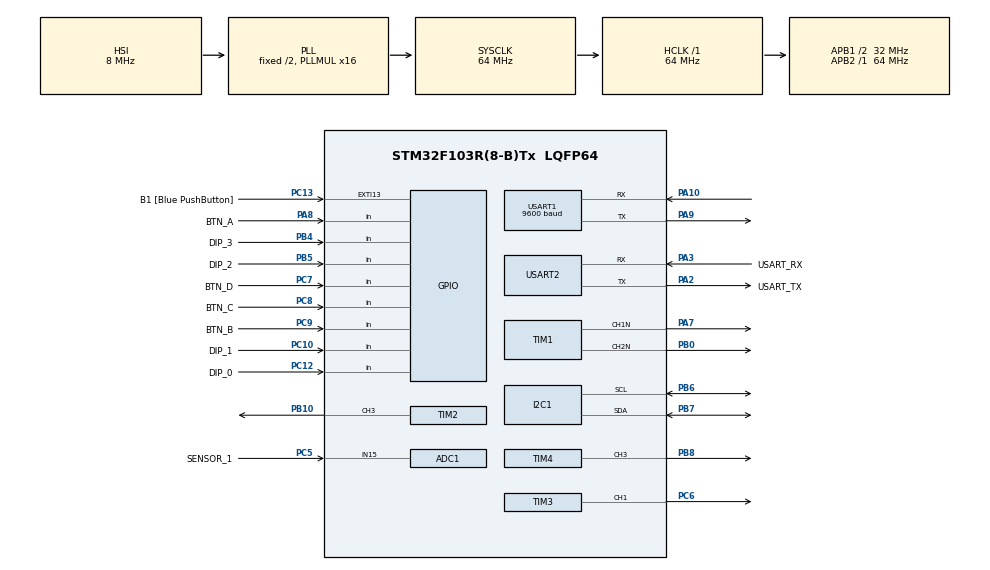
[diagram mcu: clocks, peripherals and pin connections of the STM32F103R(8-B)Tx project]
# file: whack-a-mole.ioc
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ADC1.Channel-0\#ChannelRegularConversion=ADC_CHANNEL_15
ADC1.ContinuousConvMode=DISABLE
ADC1.NbrOfConversion=1
ADC1.NbrOfConversionFlag=1
ADC1.Rank-0\#ChannelRegularConversion=1
ADC1.SamplingTime-0\#ChannelRegularConversion=ADC_SAMPLETIME_1CYCLE_5
ADC1.master=1
Mcu.Family=STM32F1
Mcu.Name=STM32F103R(8-B)Tx
Mcu.Package=LQFP64
NVIC.ADC1_2_IRQn=true\:0\:0\:false\:false\:true\:true\:true\:true
NVIC.EXTI15_10_IRQn=true\:0\:0\:false\:false\:true\:true\:true\:true
NVIC.PriorityGroup=NVIC_PRIORITYGROUP_4
NVIC.USART1_IRQn=true\:0\:0\:false\:false\:true\:true\:true\:true
PA10.Mode=Asynchronous
PA10.Signal=USART1_RX
PA13.GPIO_Label=TMS
PA13.Mode=Serial_Wire
PA13.Signal=SYS_JTMS-SWDIO
PA14.GPIO_Label=TCK
PA14.Mode=Serial_Wire
PA14.Signal=SYS_JTCK-SWCLK
PA2.GPIO_Label=USART_TX
PA2.GPIO_Mode=GPIO_MODE_AF_PP
PA2.GPIO_PuPd=GPIO_NOPULL
PA2.GPIO_Speed=GPIO_SPEED_FREQ_LOW
PA2.Mode=Asynchronous
PA2.Signal=USART2_TX
PA3.GPIO_Label=USART_RX
PA3.GPIO_Mode=GPIO_MODE_AF_PP
PA3.GPIO_PuPd=GPIO_NOPULL
PA3.GPIO_Speed=GPIO_SPEED_FREQ_LOW
PA3.Mode=Asynchronous
PA3.Signal=USART2_RX
PA7.Mode=PWM Generation1 CH1N
PA7.Signal=TIM1_CH1N
PA8.GPIO_Label=BTN_A
PA8.GPIO_PuPd=GPIO_PULLUP
PA8.Signal=GPIO_Input
PA9.Mode=Asynchronous
PA9.Signal=USART1_TX
PB0.Mode=PWM Generation2 CH2N
PB0.Signal=TIM1_CH2N
PB10.Signal=S_TIM2_CH3
PB11.Signal=I2C2_SDA
PB3.GPIO_Label=SWO
PB3.Signal=SYS_JTDO-TRACESWO
PB4.GPIO_Label=DIP_3
PB4.GPIO_PuPd=GPIO_PULLUP
PB4.Signal=GPIO_Input
PB5.GPIO_Label=DIP_2
PB5.GPIO_PuPd=GPIO_PULLUP
PB5.Signal=GPIO_Input
PB6.Mode=I2C
PB6.Signal=I2C1_SCL
PB7.Mode=I2C
PB7.Signal=I2C1_SDA
PB8.Signal=S_TIM4_CH3
PC10.GPIO_Label=DIP_1
PC10.GPIO_PuPd=GPIO_PULLUP
PC10.Signal=GPIO_Input
PC12.GPIO_Label=DIP_0
PC12.GPIO_PuPd=GPIO_PULLUP
PC12.Signal=GPIO_Input
PC13-TAMPER-RTC.GPIO_Label=B1 [Blue PushButton]
PC13-TAMPER-RTC.GPIO_PuPd=GPIO_NOPULL
PC13-TAMPER-RTC.Signal=GPXTI13
PC14-OSC32_IN.Mode=LSE-External-Oscillator
PC14-OSC32_IN.Signal=RCC_OSC32_IN
PC15-OSC32_OUT.Mode=LSE-External-Oscillator
PC15-OSC32_OUT.Signal=RCC_OSC32_OUT
PC5.GPIO_Label=SENSOR_1
PC5.Signal=ADCx_IN15
PC6.Signal=S_TIM3_CH1
PC7.GPIO_Label=BTN_D
PC7.GPIO_PuPd=GPIO_PULLUP
PC7.Signal=GPIO_Input
PC8.GPIO_Label=BTN_C
PC8.GPIO_PuPd=GPIO_PULLUP
PC8.Signal=GPIO_Input
PC9.GPIO_Label=BTN_B
PC9.GPIO_PuPd=GPIO_PULLUP
PC9.Signal=GPIO_Input
PD0-OSC_IN.Mode=HSE-External-Clock-Source
PD0-OSC_IN.Signal=RCC_OSC_IN
PD1-OSC_OUT.Mode=HSE-External-Clock-Source
PD1-OSC_OUT.Signal=RCC_OSC_OUT
ProjectManager.HeapSize=0x200
ProjectManager.StackSize=0x400
ProjectManager.TargetToolchain=STM32CubeIDE
RCC.ADCPresc=RCC_ADCPCLK2_DIV6
RCC.AHBFreq_Value=64000000
RCC.APB1CLKDivider=RCC_HCLK_DIV2
RCC.APB1Freq_Value=32000000
RCC.APB1TimFreq_Value=64000000
RCC.APB2Freq_Value=64000000
RCC.APB2TimFreq_Value=64000000
RCC.HCLKFreq_Value=64000000
RCC.PLLMUL=RCC_PLL_MUL16
RCC.RTCClockSelection=RCC_RTCCLKSOURCE_LSE
RCC.SYSCLKFreq_VALUE=64000000
RCC.SYSCLKSource=RCC_SYSCLKSOURCE_PLLCLK
RCC.USBFreq_Value=64000000
SH.ADCx_IN15.0=ADC1_IN15,IN15
SH.S_TIM2_CH3.0=TIM2_CH3,PWM Generation3 CH3
SH.S_TIM3_CH1.0=TIM3_CH1,PWM Generation1 CH1
SH.S_TIM4_CH3.0=TIM4_CH3,PWM Generation3 CH3
TIM1.Channel-PWM\ Generation1\ CH1N=TIM_CHANNEL_1
TIM1.Channel-PWM\ Generation2\ CH2N=TIM_CHANNEL_2
TIM2.Channel-PWM\ Generation3\ CH3=TIM_CHANNEL_3
TIM3.Channel-PWM\ Generation1\ CH1=TIM_CHANNEL_1
TIM4.Channel-PWM\ Generation3\ CH3=TIM_CHANNEL_3
USART1.BaudRate=9600
USART1.VirtualMode=VM_ASYNC
USART2.VirtualMode=VM_ASYNC
board=NUCLEO-F103RB

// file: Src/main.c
/* USER CODE BEGIN Header */
/**
  ******************************************************************************
  * @file           : main.c
  * @brief          : Main program body
  ******************************************************************************
  * @attention
  *
  * Copyright (c) 2026 STMicroelectronics.
  * All rights reserved.
  *
  * This software is licensed under terms that can be found in the LICENSE file
  * in the root directory of this software component.
  * If no LICENSE file comes with this software, it is provided AS-IS.
  *
  ******************************************************************************
  */
/* USER CODE END Header */
#include "main.h"

/* USER CODE BEGIN Includes */
#include "task_scheduler.h"
#include "lcd.h"
#include "low_power.h"

/* USER CODE END Includes */

ADC_HandleTypeDef hadc1;

I2C_HandleTypeDef hi2c1;

TIM_HandleTypeDef htim1;
TIM_HandleTypeDef htim2;
TIM_HandleTypeDef htim3;
TIM_HandleTypeDef htim4;

UART_HandleTypeDef huart1;
UART_HandleTypeDef huart2;

void SystemClock_Config(void);
static void MX_GPIO_Init(void);
static void MX_USART2_UART_Init(void);
static void MX_TIM3_Init(void);
static void MX_TIM1_Init(void);
static void MX_TIM2_Init(void);
static void MX_TIM4_Init(void);
static void MX_ADC1_Init(void);
static void MX_I2C1_Init(void);
static void MX_USART1_UART_Init(void);

int main(void)
{

  /* MCU Configuration--------------------------------------------------------*/

  /* Reset of all peripherals, Initializes the Flash interface and the Systick. */
  HAL_Init();

  /* Configure the system clock */
  SystemClock_Config();

  /* Initialize all configured peripherals */
  MX_GPIO_Init();
  MX_USART2_UART_Init();
  MX_TIM3_Init();
  MX_TIM1_Init();
  MX_TIM2_Init();
  MX_TIM4_Init();
  MX_ADC1_Init();
  MX_I2C1_Init();
  MX_USART1_UART_Init();
  /* USER CODE BEGIN 2 */
  schedulerInit();

  /* USER CODE END 2 */

  /* Infinite loop */
  /* USER CODE BEGIN WHILE */
  while (1)
  {
	  schedulerUpdate();
	  lowPowerEnterIdle();

    /* USER CODE END WHILE */

  }
}

void SystemClock_Config(void)
{
  RCC_OscInitTypeDef RCC_OscInitStruct = {0};
  RCC_ClkInitTypeDef RCC_ClkInitStruct = {0};
  RCC_PeriphCLKInitTypeDef PeriphClkInit = {0};

  /** Initializes the RCC Oscillators according to the specified parameters
  * in the RCC_OscInitTypeDef structure.
  */
  RCC_OscInitStruct.OscillatorType = RCC_OSCILLATORTYPE_HSI;
  RCC_OscInitStruct.HSIState = RCC_HSI_ON;
  RCC_OscInitStruct.HSICalibrationValue = RCC_HSICALIBRATION_DEFAULT;
  RCC_OscInitStruct.PLL.PLLState = RCC_PLL_ON;
  RCC_OscInitStruct.PLL.PLLSource = RCC_PLLSOURCE_HSI_DIV2;
  RCC_OscInitStruct.PLL.PLLMUL = RCC_PLL_MUL16;
  if (HAL_RCC_OscConfig(&RCC_OscInitStruct) != HAL_OK)
  {
    Error_Handler();
  }

  /** Initializes the CPU, AHB and APB buses clocks
  */
  RCC_ClkInitStruct.ClockType = RCC_CLOCKTYPE_HCLK|RCC_CLOCKTYPE_SYSCLK
                              |RCC_CLOCKTYPE_PCLK1|RCC_CLOCKTYPE_PCLK2;
  RCC_ClkInitStruct.SYSCLKSource = RCC_SYSCLKSOURCE_PLLCLK;
  RCC_ClkInitStruct.AHBCLKDivider = RCC_SYSCLK_DIV1;
  RCC_ClkInitStruct.APB1CLKDivider = RCC_HCLK_DIV2;
  RCC_ClkInitStruct.APB2CLKDivider = RCC_HCLK_DIV1;

  if (HAL_RCC_ClockConfig(&RCC_ClkInitStruct, FLASH_LATENCY_2) != HAL_OK)
  {
    Error_Handler();
  }
  PeriphClkInit.PeriphClockSelection = RCC_PERIPHCLK_ADC;
  PeriphClkInit.AdcClockSelection = RCC_ADCPCLK2_DIV6;
  if (HAL_RCCEx_PeriphCLKConfig(&PeriphClkInit) != HAL_OK)
  {
    Error_Handler();
  }
}

static void MX_ADC1_Init(void)
{

  ADC_ChannelConfTypeDef sConfig = {0};

  /** Common config
  */
  hadc1.Instance = ADC1;
  hadc1.Init.ScanConvMode = ADC_SCAN_DISABLE;
  hadc1.Init.ContinuousConvMode = DISABLE;
  hadc1.Init.DiscontinuousConvMode = DISABLE;
  hadc1.Init.ExternalTrigConv = ADC_SOFTWARE_START;
  hadc1.Init.DataAlign = ADC_DATAALIGN_RIGHT;
  hadc1.Init.NbrOfConversion = 1;
  if (HAL_ADC_Init(&hadc1) != HAL_OK)
  {
    Error_Handler();
  }

  /** Configure Regular Channel
  */
  sConfig.Channel = ADC_CHANNEL_15;
  sConfig.Rank = ADC_REGULAR_RANK_1;
  sConfig.SamplingTime = ADC_SAMPLETIME_1CYCLE_5;
  if (HAL_ADC_ConfigChannel(&hadc1, &sConfig) != HAL_OK)
  {
    Error_Handler();
  }

}

static void MX_I2C1_Init(void)
{

  hi2c1.Instance = I2C1;
  hi2c1.Init.ClockSpeed = 100000;
  hi2c1.Init.DutyCycle = I2C_DUTYCYCLE_2;
  hi2c1.Init.OwnAddress1 = 0;
  hi2c1.Init.AddressingMode = I2C_ADDRESSINGMODE_7BIT;
  hi2c1.Init.DualAddressMode = I2C_DUALADDRESS_DISABLE;
  hi2c1.Init.OwnAddress2 = 0;
  hi2c1.Init.GeneralCallMode = I2C_GENERALCALL_DISABLE;
  hi2c1.Init.NoStretchMode = I2C_NOSTRETCH_DISABLE;
  if (HAL_I2C_Init(&hi2c1) != HAL_OK)
  {
    Error_Handler();
  }

}

static void MX_TIM1_Init(void)
{

  TIM_MasterConfigTypeDef sMasterConfig = {0};
  TIM_OC_InitTypeDef sConfigOC = {0};
  TIM_BreakDeadTimeConfigTypeDef sBreakDeadTimeConfig = {0};

  htim1.Instance = TIM1;
  htim1.Init.Prescaler = 0;
  htim1.Init.CounterMode = TIM_COUNTERMODE_UP;
  htim1.Init.Period = 65535;
  htim1.Init.ClockDivision = TIM_CLOCKDIVISION_DIV1;
  htim1.Init.RepetitionCounter = 0;
  htim1.Init.AutoReloadPreload = TIM_AUTORELOAD_PRELOAD_DISABLE;
  if (HAL_TIM_PWM_Init(&htim1) != HAL_OK)
  {
    Error_Handler();
  }
  sMasterConfig.MasterOutputTrigger = TIM_TRGO_RESET;
  sMasterConfig.MasterSlaveMode = TIM_MASTERSLAVEMODE_DISABLE;
  if (HAL_TIMEx_MasterConfigSynchronization(&htim1, &sMasterConfig) != HAL_OK)
  {
    Error_Handler();
  }
  sConfigOC.OCMode = TIM_OCMODE_PWM1;
  sConfigOC.Pulse = 0;
  sConfigOC.OCPolarity = TIM_OCPOLARITY_HIGH;
  sConfigOC.OCNPolarity = TIM_OCNPOLARITY_HIGH;
  sConfigOC.OCFastMode = TIM_OCFAST_DISABLE;
  sConfigOC.OCIdleState = TIM_OCIDLESTATE_RESET;
  sConfigOC.OCNIdleState = TIM_OCNIDLESTATE_RESET;
  if (HAL_TIM_PWM_ConfigChannel(&htim1, &sConfigOC, TIM_CHANNEL_1) != HAL_OK)
  {
    Error_Handler();
  }
  if (HAL_TIM_PWM_ConfigChannel(&htim1, &sConfigOC, TIM_CHANNEL_2) != HAL_OK)
  {
    Error_Handler();
  }
  sBreakDeadTimeConfig.OffStateRunMode = TIM_OSSR_DISABLE;
  sBreakDeadTimeConfig.OffStateIDLEMode = TIM_OSSI_DISABLE;
  sBreakDeadTimeConfig.LockLevel = TIM_LOCKLEVEL_OFF;
  sBreakDeadTimeConfig.DeadTime = 0;
  sBreakDeadTimeConfig.BreakState = TIM_BREAK_DISABLE;
  sBreakDeadTimeConfig.BreakPolarity = TIM_BREAKPOLARITY_HIGH;
  sBreakDeadTimeConfig.AutomaticOutput = TIM_AUTOMATICOUTPUT_DISABLE;
  if (HAL_TIMEx_ConfigBreakDeadTime(&htim1, &sBreakDeadTimeConfig) != HAL_OK)
  {
    Error_Handler();
  }
  HAL_TIM_MspPostInit(&htim1);

}

static void MX_TIM2_Init(void)
{

  TIM_MasterConfigTypeDef sMasterConfig = {0};
  TIM_OC_InitTypeDef sConfigOC = {0};

  htim2.Instance = TIM2;
  htim2.Init.Prescaler = 0;
  htim2.Init.CounterMode = TIM_COUNTERMODE_UP;
  htim2.Init.Period = 65535;
  htim2.Init.ClockDivision = TIM_CLOCKDIVISION_DIV1;
  htim2.Init.AutoReloadPreload = TIM_AUTORELOAD_PRELOAD_DISABLE;
  if (HAL_TIM_PWM_Init(&htim2) != HAL_OK)
  {
    Error_Handler();
  }
  sMasterConfig.MasterOutputTrigger = TIM_TRGO_RESET;
  sMasterConfig.MasterSlaveMode = TIM_MASTERSLAVEMODE_DISABLE;
  if (HAL_TIMEx_MasterConfigSynchronization(&htim2, &sMasterConfig) != HAL_OK)
  {
    Error_Handler();
  }
  sConfigOC.OCMode = TIM_OCMODE_PWM1;
  sConfigOC.Pulse = 0;
  sConfigOC.OCPolarity = TIM_OCPOLARITY_HIGH;
  sConfigOC.OCFastMode = TIM_OCFAST_DISABLE;
  if (HAL_TIM_PWM_ConfigChannel(&htim2, &sConfigOC, TIM_CHANNEL_3) != HAL_OK)
  {
    Error_Handler();
  }
  HAL_TIM_MspPostInit(&htim2);

}

static void MX_TIM3_Init(void)
{

  TIM_MasterConfigTypeDef sMasterConfig = {0};
  TIM_OC_InitTypeDef sConfigOC = {0};

  htim3.Instance = TIM3;
  htim3.Init.Prescaler = 0;
  htim3.Init.CounterMode = TIM_COUNTERMODE_UP;
  htim3.Init.Period = 65535;
  htim3.Init.ClockDivision = TIM_CLOCKDIVISION_DIV1;
  htim3.Init.AutoReloadPreload = TIM_AUTORELOAD_PRELOAD_DISABLE;
  if (HAL_TIM_PWM_Init(&htim3) != HAL_OK)
  {
    Error_Handler();
  }
  sMasterConfig.MasterOutputTrigger = TIM_TRGO_RESET;
  sMasterConfig.MasterSlaveMode = TIM_MASTERSLAVEMODE_DISABLE;
  if (HAL_TIMEx_MasterConfigSynchronization(&htim3, &sMasterConfig) != HAL_OK)
  {
    Error_Handler();
  }
  sConfigOC.OCMode = TIM_OCMODE_PWM1;
  sConfigOC.Pulse = 0;
  sConfigOC.OCPolarity = TIM_OCPOLARITY_HIGH;
  sConfigOC.OCFastMode = TIM_OCFAST_DISABLE;
  if (HAL_TIM_PWM_ConfigChannel(&htim3, &sConfigOC, TIM_CHANNEL_1) != HAL_OK)
  {
    Error_Handler();
  }
  HAL_TIM_MspPostInit(&htim3);

}

static void MX_TIM4_Init(void)
{

  TIM_MasterConfigTypeDef sMasterConfig = {0};
  TIM_OC_InitTypeDef sConfigOC = {0};

  htim4.Instance = TIM4;
  htim4.Init.Prescaler = 0;
  htim4.Init.CounterMode = TIM_COUNTERMODE_UP;
  htim4.Init.Period = 65535;
  htim4.Init.ClockDivision = TIM_CLOCKDIVISION_DIV1;
  htim4.Init.AutoReloadPreload = TIM_AUTORELOAD_PRELOAD_DISABLE;
  if (HAL_TIM_PWM_Init(&htim4) != HAL_OK)
  {
    Error_Handler();
  }
  sMasterConfig.MasterOutputTrigger = TIM_TRGO_RESET;
  sMasterConfig.MasterSlaveMode = TIM_MASTERSLAVEMODE_DISABLE;
  if (HAL_TIMEx_MasterConfigSynchronization(&htim4, &sMasterConfig) != HAL_OK)
  {
    Error_Handler();
  }
  sConfigOC.OCMode = TIM_OCMODE_PWM1;
  sConfigOC.Pulse = 0;
  sConfigOC.OCPolarity = TIM_OCPOLARITY_HIGH;
  sConfigOC.OCFastMode = TIM_OCFAST_DISABLE;
  if (HAL_TIM_PWM_ConfigChannel(&htim4, &sConfigOC, TIM_CHANNEL_3) != HAL_OK)
  {
    Error_Handler();
  }
  HAL_TIM_MspPostInit(&htim4);

}

static void MX_USART1_UART_Init(void)
{

  huart1.Instance = USART1;
  huart1.Init.BaudRate = 9600;
  huart1.Init.WordLength = UART_WORDLENGTH_8B;
  huart1.Init.StopBits = UART_STOPBITS_1;
  huart1.Init.Parity = UART_PARITY_NONE;
  huart1.Init.Mode = UART_MODE_TX_RX;
  huart1.Init.HwFlowCtl = UART_HWCONTROL_NONE;
  huart1.Init.OverSampling = UART_OVERSAMPLING_16;
  if (HAL_UART_Init(&huart1) != HAL_OK)
  {
    Error_Handler();
  }

}

static void MX_USART2_UART_Init(void)
{

  huart2.Instance = USART2;
  huart2.Init.BaudRate = 115200;
  huart2.Init.WordLength = UART_WORDLENGTH_8B;
  huart2.Init.StopBits = UART_STOPBITS_1;
  huart2.Init.Parity = UART_PARITY_NONE;
  huart2.Init.Mode = UART_MODE_TX_RX;
  huart2.Init.HwFlowCtl = UART_HWCONTROL_NONE;
  huart2.Init.OverSampling = UART_OVERSAMPLING_16;
  if (HAL_UART_Init(&huart2) != HAL_OK)
  {
    Error_Handler();
  }

}

static void MX_GPIO_Init(void)
{
  GPIO_InitTypeDef GPIO_InitStruct = {0};

  /* GPIO Ports Clock Enable */
  __HAL_RCC_GPIOC_CLK_ENABLE();
  __HAL_RCC_GPIOD_CLK_ENABLE();
  __HAL_RCC_GPIOA_CLK_ENABLE();
  __HAL_RCC_GPIOB_CLK_ENABLE();

  /*Configure GPIO pin : B1_Pin */
  GPIO_InitStruct.Pin = B1_Pin;
  GPIO_InitStruct.Mode = GPIO_MODE_IT_RISING;
  GPIO_InitStruct.Pull = GPIO_NOPULL;
  HAL_GPIO_Init(B1_GPIO_Port, &GPIO_InitStruct);

  /*Configure GPIO pin : PB11 */
  GPIO_InitStruct.Pin = GPIO_PIN_11;
  GPIO_InitStruct.Mode = GPIO_MODE_AF_OD;
  GPIO_InitStruct.Speed = GPIO_SPEED_FREQ_HIGH;
  HAL_GPIO_Init(GPIOB, &GPIO_InitStruct);

  /*Configure GPIO pins : BTN_D_Pin BTN_C_Pin BTN_B_Pin DIP_1_Pin
                           DIP_0_Pin */
  GPIO_InitStruct.Pin = BTN_D_Pin|BTN_C_Pin|BTN_B_Pin|DIP_1_Pin
                          |DIP_0_Pin;
  GPIO_InitStruct.Mode = GPIO_MODE_INPUT;
  GPIO_InitStruct.Pull = GPIO_PULLUP;
  HAL_GPIO_Init(GPIOC, &GPIO_InitStruct);

  /*Configure GPIO pin : BTN_A_Pin */
  GPIO_InitStruct.Pin = BTN_A_Pin;
  GPIO_InitStruct.Mode = GPIO_MODE_INPUT;
  GPIO_InitStruct.Pull = GPIO_PULLUP;
  HAL_GPIO_Init(BTN_A_GPIO_Port, &GPIO_InitStruct);

  /*Configure GPIO pins : DIP_3_Pin DIP_2_Pin */
  GPIO_InitStruct.Pin = DIP_3_Pin|DIP_2_Pin;
  GPIO_InitStruct.Mode = GPIO_MODE_INPUT;
  GPIO_InitStruct.Pull = GPIO_PULLUP;
  HAL_GPIO_Init(GPIOB, &GPIO_InitStruct);

  /* EXTI interrupt init*/
  HAL_NVIC_SetPriority(EXTI15_10_IRQn, 0, 0);
  HAL_NVIC_EnableIRQ(EXTI15_10_IRQn);

}

void Error_Handler(void)
{
  __disable_irq();
  while (1)
  {
  }
}
